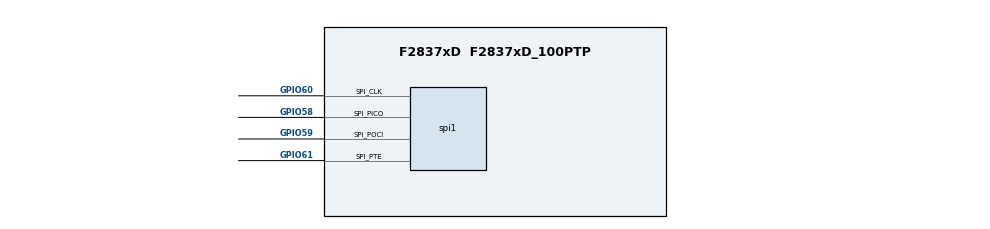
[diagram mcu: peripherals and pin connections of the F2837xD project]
/**
 * @cliArgs --device "F2837xD" --part "F2837xD_100PTP" --package "F2837xD_100PTP" --context "CPU1" --product "C2000WARE@5.04.00.00"
 * @versions {"tool":"1.23.0+4000"}
 */

/**
 * Import the modules used in this configuration.
 */
const spi  = scripting.addModule("/driverlib/spi.js", {}, false);
const spi1 = spi.addInstance();

/**
 * Write custom configuration values to the imported modules.
 */
spi1.$name                   = "mySPI0";
spi1.mode                    = "SPI_MODE_CONTROLLER";
spi1.emulationMode           = "SPI_EMULATION_STOP_AFTER_TRANSMIT";
spi1.useInterrupts           = false;
spi1.useFifo                 = false;
spi1.spi.$assign             = "SPIA";
spi1.spi.spi_picoPin.$assign = "GPIO58";
spi1.spi.spi_pociPin.$assign = "GPIO59";
spi1.spi.spi_clkPin.$assign  = "GPIO60";
spi1.spi.spi_ptePin.$assign  = "GPIO61";
spi1.picoQual.$name          = "myGPIOQUAL0";
spi1.pociQual.$name          = "myGPIOQUAL1";
spi1.clkQual.$name           = "myGPIOQUAL2";
spi1.pteQual.$name           = "myGPIOQUAL3";
